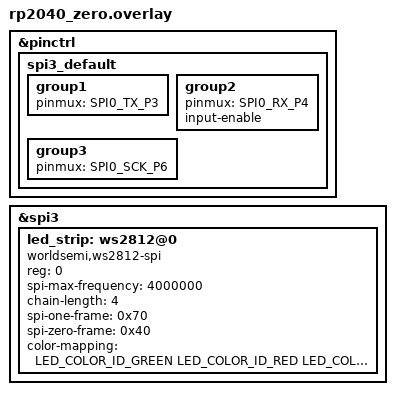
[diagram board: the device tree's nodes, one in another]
/*
 * Copyright (c) 2025 Allister MacLeod
 * SPDX-License-Identifier: MIT
 */

#include <dt-bindings/pinctrl/rpi-pico-rp2040-pinctrl.h>
#include <dt-bindings/led/led.h>

&pinctrl {
  spi3_default: spi3_default {
    group1 {
      pinmux = <SPI0_TX_P3>;
    };
    group2 {
      pinmux = <SPI0_RX_P4>;
      input-enable;
    };
    group3 {
      pinmux = <SPI0_SCK_P6>;
    };
  };
};

&spi3 {
  led_strip: ws2812@0 {
    compatible = "worldsemi,ws2812-spi";

    reg = <0>;
    spi-max-frequency = <4000000>;

    chain-length = <4>;
    spi-one-frame = <0x70>;
    spi-zero-frame = <0x40>;
    color-mapping = <LED_COLOR_ID_GREEN LED_COLOR_ID_RED LED_COLOR_ID_BLUE>;
  };
};
